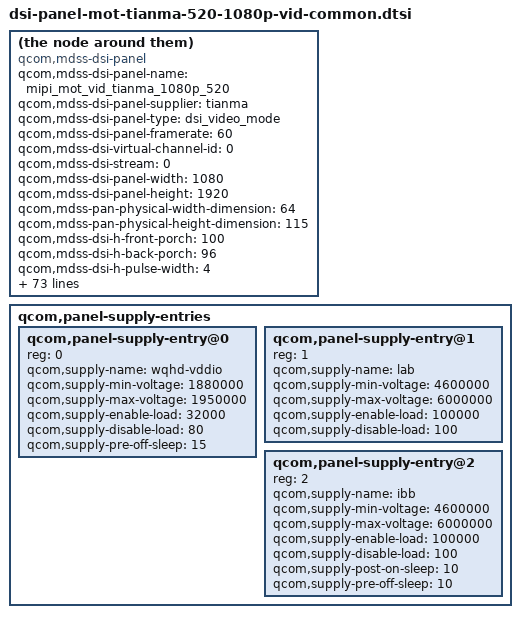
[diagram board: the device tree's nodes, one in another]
/* Copyright (c) 2016, The Linux Foundation. All rights reserved.
 *
 * This program is free software; you can redistribute it and/or modify
 * it under the terms of the GNU General Public License version 2 and
 * only version 2 as published by the Free Software Foundation.
 *
 * This program is distributed in the hope that it will be useful,
 * but WITHOUT ANY WARRANTY; without even the implied warranty of
 * MERCHANTABILITY or FITNESS FOR A PARTICULAR PURPOSE.  See the
 * GNU General Public License for more details.
 */

compatible = "qcom,mdss-dsi-panel";
qcom,mdss-dsi-panel-name = "mipi_mot_vid_tianma_1080p_520";
qcom,mdss-dsi-panel-supplier = "tianma";
qcom,mdss-dsi-panel-type = "dsi_video_mode";
qcom,mdss-dsi-panel-framerate = <60>;
qcom,mdss-dsi-virtual-channel-id = <0>;
qcom,mdss-dsi-stream = <0>;
qcom,mdss-dsi-panel-width = <1080>;
qcom,mdss-dsi-panel-height = <1920>;
qcom,mdss-pan-physical-width-dimension = <64>;
qcom,mdss-pan-physical-height-dimension = <115>;
qcom,mdss-dsi-h-front-porch = <100>;
qcom,mdss-dsi-h-back-porch = <96>;
qcom,mdss-dsi-h-pulse-width = <4>;
qcom,mdss-dsi-h-sync-skew = <0>;
qcom,mdss-dsi-v-back-porch = <16>;
qcom,mdss-dsi-v-front-porch = <16>;
qcom,mdss-dsi-v-pulse-width = <2>;
qcom,mdss-dsi-h-left-border = <0>;
qcom,mdss-dsi-h-right-border = <0>;
qcom,mdss-dsi-v-top-border = <0>;
qcom,mdss-dsi-v-bottom-border = <0>;
qcom,mdss-dsi-bpp = <24>;
qcom,mdss-dsi-underflow-color = <0xff>;
qcom,mdss-dsi-border-color = <0>;
qcom,mdss-dsi-on-command = [
	29 01 00 00 00 00 02 00 00
	29 01 00 00 00 00 04 ff 87 16 01
	29 01 00 00 00 00 02 00 80
	29 01 00 00 00 00 03 FF 87 16
	29 01 00 00 00 00 02 00 A0
	29 01 00 00 00 00 0d D6 18 12 0f 11 12 11 0f 13 14 16 1b 1b
	29 01 00 00 00 00 02 00 B0
	29 01 00 00 00 00 0d D6 7e 92 9a 91 76 70 7a 7d 6a 7d 6e 81
	29 01 00 00 00 00 02 00 C0
	29 01 00 00 00 00 0d D6 6e 81 95 94 c1 cc d1 b7 b8 87 87 72
	29 01 00 00 00 00 02 00 D0
	29 01 00 00 00 00 0d D6 6b 96 95 9e 9a 9b 8f a5 aa aa 80 5c
	29 01 00 00 00 00 02 91 80
	29 01 00 00 00 00 02 00 B4
	29 01 00 00 00 00 02 C0 50
	15 01 00 00 00 00 02 51 CC
	15 01 00 00 00 00 02 53 2C
	15 01 00 00 00 00 02 55 01
	05 01 00 00 82 00 02 11 00
	05 01 00 00 0A 00 02 29 00];	/* display on */
qcom,mdss-dsi-off-command = [
	05 01 00 00 23 00 01 28		/* display_off */
	05 01 00 00 78 00 01 10];	/* enter sleep mode */


qcom,mdss-dsi-on-command-state = "dsi_lp_mode";
qcom,mdss-dsi-off-command-state = "dsi_lp_mode";

qcom,mdss-dsi-cabc-ui-command = [15 01 00 00 00 00 02 55 01];
qcom,mdss-dsi-cabc-ui-command-state = "dsi_hs_mode";
qcom,mdss-dsi-cabc-mv-command = [15 01 00 00 00 00 02 55 03];
qcom,mdss-dsi-cabc-mv-command-state = "dsi_hs_mode";
qcom,mdss-dsi-cabc-dis-command = [15 01 00 00 00 00 02 55 00];
qcom,mdss-dsi-cabc-dis-command-state = "dsi_hs_mode";
qcom,mdss-dsi-hbm-on-command = [15 01 00 00 00 00 02 51 FF];
qcom,mdss-dsi-hbm-on-command-state = "dsi_hs_mode";
qcom,mdss-dsi-hbm-off-command = [15 01 00 00 00 00 02 51 CC];
qcom,mdss-dsi-hbm-off-command-state = "dsi_hs_mode";
qcom,mdss-dsi-hbm-type = "lcd-dcs-wled";

qcom,mdss-dsi-h-sync-pulse = <0>;
qcom,mdss-dsi-traffic-mode = "burst_mode";
qcom,mdss-dsi-bllp-eof-power-mode;
qcom,mdss-dsi-bllp-power-mode;
qcom,mdss-dsi-lane-0-state;
qcom,mdss-dsi-lane-1-state;
qcom,mdss-dsi-lane-2-state;
qcom,mdss-dsi-lane-3-state;
qcom,mdss-dsi-panel-timings = [00 19 05 06 0A 0F 05 06 05 03 04 00];
qcom,mdss-dsi-panel-timings-phy-v2 = [24 1f 08 09 05 03 04 a0
	24 1f 08 09 05 03 04 a0
	24 1f 08 09 05 03 04 a0
	24 1f 08 09 05 03 04 a0
	24 1b 08 09 05 03 04 a0];
qcom,mdss-dsi-t-clk-post = <0x0d>;
qcom,mdss-dsi-t-clk-pre = <0x30>;
qcom,mdss-dsi-bl-min-level = <1>;
qcom,mdss-dsi-bl-max-level = <4095>;
qcom,mdss-dsi-dma-trigger = "trigger_sw";
qcom,mdss-dsi-mdp-trigger = "none";
qcom,mdss-dsi-bl-pmic-control-type = "bl_ctrl_wled";
qcom,mdss-dsi-reset-sequence = <1 5>, <0 5>, <1 5>;
qcom,mdss-dsi-lp11-init;
qcom,mdss-dsi-lp11-lcdb-reset;
qcom,mdss-dsi-tx-eot-append;
qcom,mdss-dsi-init-delay-us = <50000>;
qcom,mdss-dsi-bl-shutdown-dcs;

qcom,esd-check-enabled;
qcom,mdss-dsi-panel-status-check-mode = "reg_read";
qcom,mdss-dsi-panel-status-read-length = <1>;
qcom,mdss-dsi-panel-status-command = [06 01 00 01 00 00 01 0A];
qcom,mdss-dsi-panel-status-command-state = "dsi_hs_mode";
qcom,mdss-dsi-panel-status-value = <0x9c>;

qcom,panel-supply-entries {
	#address-cells = <1>;
	#size-cells = <0>;

	qcom,panel-supply-entry@0 {
		reg = <0>;
		qcom,supply-name = "wqhd-vddio";
		qcom,supply-min-voltage = <1880000>;
		qcom,supply-max-voltage = <1950000>;
		qcom,supply-enable-load = <32000>;
		qcom,supply-disable-load = <80>;
		qcom,supply-pre-off-sleep = <15>;
	};

	qcom,panel-supply-entry@1 {
		reg = <1>;
		qcom,supply-name = "lab";
		qcom,supply-min-voltage = <4600000>;
		qcom,supply-max-voltage = <6000000>;
		qcom,supply-enable-load = <100000>;
		qcom,supply-disable-load = <100>;
	};

	qcom,panel-supply-entry@2 {
		reg = <2>;
		qcom,supply-name = "ibb";
		qcom,supply-min-voltage = <4600000>;
		qcom,supply-max-voltage = <6000000>;
		qcom,supply-enable-load = <100000>;
		qcom,supply-disable-load = <100>;
		qcom,supply-post-on-sleep = <10>;
		qcom,supply-pre-off-sleep = <10>;
	};
};
